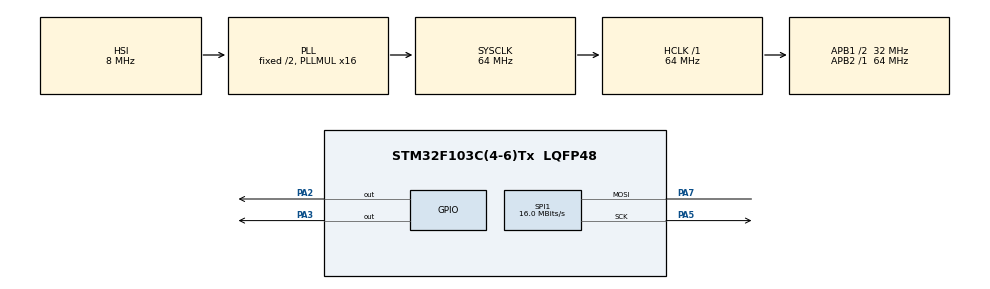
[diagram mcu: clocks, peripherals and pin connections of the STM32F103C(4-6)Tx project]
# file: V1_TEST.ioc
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Mcu.Family=STM32F1
Mcu.Name=STM32F103C(4-6)Tx
Mcu.Package=LQFP48
NVIC.PriorityGroup=NVIC_PRIORITYGROUP_4
PA2.Signal=GPIO_Output
PA3.Signal=GPIO_Output
PA4.Signal=SPI1_NSS
PA5.Mode=Simplex_Bidirectional_Master
PA5.Signal=SPI1_SCK
PA7.Mode=Simplex_Bidirectional_Master
PA7.Signal=SPI1_MOSI
ProjectManager.HeapSize=0x200
ProjectManager.StackSize=0x400
ProjectManager.TargetToolchain=STM32CubeIDE
RCC.AHBFreq_Value=64000000
RCC.APB1CLKDivider=RCC_HCLK_DIV2
RCC.APB1Freq_Value=32000000
RCC.APB1TimFreq_Value=64000000
RCC.APB2Freq_Value=64000000
RCC.APB2TimFreq_Value=64000000
RCC.HCLKFreq_Value=64000000
RCC.PLLMUL=RCC_PLL_MUL16
RCC.SYSCLKFreq_VALUE=64000000
RCC.SYSCLKSource=RCC_SYSCLKSOURCE_PLLCLK
RCC.USBFreq_Value=64000000
SPI1.BaudRatePrescaler=SPI_BAUDRATEPRESCALER_4
SPI1.CalculateBaudRate=16.0 MBits/s
SPI1.Direction=SPI_DIRECTION_1LINE
SPI1.Mode=SPI_MODE_MASTER
SPI1.VirtualType=VM_MASTER
VP_SYS_VS_ND.Mode=No_Debug
board=custom

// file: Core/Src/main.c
/* USER CODE BEGIN Header */
/**
  ******************************************************************************
  * @file           : main.c
  * @brief          : Main program body
  ******************************************************************************
  * @attention
  *
  * Copyright (c) 2025 STMicroelectronics.
  * All rights reserved.
  *
  * This software is licensed under terms that can be found in the LICENSE file
  * in the root directory of this software component.
  * If no LICENSE file comes with this software, it is provided AS-IS.
  *
  ******************************************************************************
  */
/* USER CODE END Header */
#include "main.h"
#include"sh1106.h"
#include"Image_BMP.h"
#include"font5x7.h"
#include"font7x10.h"

SPI_HandleTypeDef hspi1;
int SOC_Var = 65 ;
int STOP_W_Var = 1.5;

void SystemClock_Config(void);
static void MX_GPIO_Init(void);
static void MX_SPI1_Init(void);

int main(void)
{

  /* MCU Configuration--------------------------------------------------------*/

  /* Reset of all peripherals, Initializes the Flash interface and the Systick. */
  HAL_Init();

  /* Configure the system clock */
  SystemClock_Config();

  /* Initialize all configured peripherals */
  MX_GPIO_Init();
  MX_SPI1_Init();
  /* USER CODE BEGIN 2 */
  SH1106_Init();

      // Set normal orientation
      SH1106_Orientation(LCD_ORIENT_NORMAL);

      // 1?? Draw fullscreen bitmap
      LCD_DrawBitmapFullscreen(gImage_Image_BMP);
      SH1106_Flush();

      HAL_Delay(2000); // 2 seconds

      // 2?? Clear display
      SH1106_Fill(0x00);
      SH1106_Flush();

//      // 3?? Display text lines
//      uint8_t y = 0;
//
//      LCD_PutStr(0, y, "SOC:",  fnt7x10 );
////      y += Font_7x10.font_Height + 2;
//
//      LCD_PutStr(0, y, "STOP_W:",  fnt7x10 );
////      y +=/ Font_7x10.font_Height + 2;
//
//      LCD_PutStr(0, y, "T_Voltage:",  fnt7x10 );
//
////       flush to update display
//      SH1106_Flush();
//
  /* USER CODE END 2 */

  /* Infinite loop */
  while (1)
  {

  }
}

void SystemClock_Config(void)
{
  RCC_OscInitTypeDef RCC_OscInitStruct = {0};
  RCC_ClkInitTypeDef RCC_ClkInitStruct = {0};

  /** Initializes the RCC Oscillators according to the specified parameters
  * in the RCC_OscInitTypeDef structure.
  */
  RCC_OscInitStruct.OscillatorType = RCC_OSCILLATORTYPE_HSI;
  RCC_OscInitStruct.HSIState = RCC_HSI_ON;
  RCC_OscInitStruct.HSICalibrationValue = RCC_HSICALIBRATION_DEFAULT;
  RCC_OscInitStruct.PLL.PLLState = RCC_PLL_ON;
  RCC_OscInitStruct.PLL.PLLSource = RCC_PLLSOURCE_HSI_DIV2;
  RCC_OscInitStruct.PLL.PLLMUL = RCC_PLL_MUL16;
  if (HAL_RCC_OscConfig(&RCC_OscInitStruct) != HAL_OK)
  {
    Error_Handler();
  }

  /** Initializes the CPU, AHB and APB buses clocks
  */
  RCC_ClkInitStruct.ClockType = RCC_CLOCKTYPE_HCLK|RCC_CLOCKTYPE_SYSCLK
                              |RCC_CLOCKTYPE_PCLK1|RCC_CLOCKTYPE_PCLK2;
  RCC_ClkInitStruct.SYSCLKSource = RCC_SYSCLKSOURCE_PLLCLK;
  RCC_ClkInitStruct.AHBCLKDivider = RCC_SYSCLK_DIV1;
  RCC_ClkInitStruct.APB1CLKDivider = RCC_HCLK_DIV2;
  RCC_ClkInitStruct.APB2CLKDivider = RCC_HCLK_DIV1;

  if (HAL_RCC_ClockConfig(&RCC_ClkInitStruct, FLASH_LATENCY_2) != HAL_OK)
  {
    Error_Handler();
  }
}

static void MX_SPI1_Init(void)
{

  /* SPI1 parameter configuration*/
  hspi1.Instance = SPI1;
  hspi1.Init.Mode = SPI_MODE_MASTER;
  hspi1.Init.Direction = SPI_DIRECTION_1LINE;
  hspi1.Init.DataSize = SPI_DATASIZE_8BIT;
  hspi1.Init.CLKPolarity = SPI_POLARITY_LOW;
  hspi1.Init.CLKPhase = SPI_PHASE_1EDGE;
  hspi1.Init.NSS = SPI_NSS_SOFT;
  hspi1.Init.BaudRatePrescaler = SPI_BAUDRATEPRESCALER_4;
  hspi1.Init.FirstBit = SPI_FIRSTBIT_MSB;
  hspi1.Init.TIMode = SPI_TIMODE_DISABLE;
  hspi1.Init.CRCCalculation = SPI_CRCCALCULATION_DISABLE;
  hspi1.Init.CRCPolynomial = 10;
  if (HAL_SPI_Init(&hspi1) != HAL_OK)
  {
    Error_Handler();
  }

}

static void MX_GPIO_Init(void)
{
  GPIO_InitTypeDef GPIO_InitStruct = {0};

  /* GPIO Ports Clock Enable */
  __HAL_RCC_GPIOA_CLK_ENABLE();

  /*Configure GPIO pin Output Level */
  HAL_GPIO_WritePin(GPIOA, GPIO_PIN_2|GPIO_PIN_3, GPIO_PIN_RESET);

  /*Configure GPIO pins : PA2 PA3 */
  GPIO_InitStruct.Pin = GPIO_PIN_2|GPIO_PIN_3;
  GPIO_InitStruct.Mode = GPIO_MODE_OUTPUT_PP;
  GPIO_InitStruct.Pull = GPIO_NOPULL;
  GPIO_InitStruct.Speed = GPIO_SPEED_FREQ_LOW;
  HAL_GPIO_Init(GPIOA, &GPIO_InitStruct);

}

void Error_Handler(void)
{
  __disable_irq();
  while (1)
  {
  }
}
